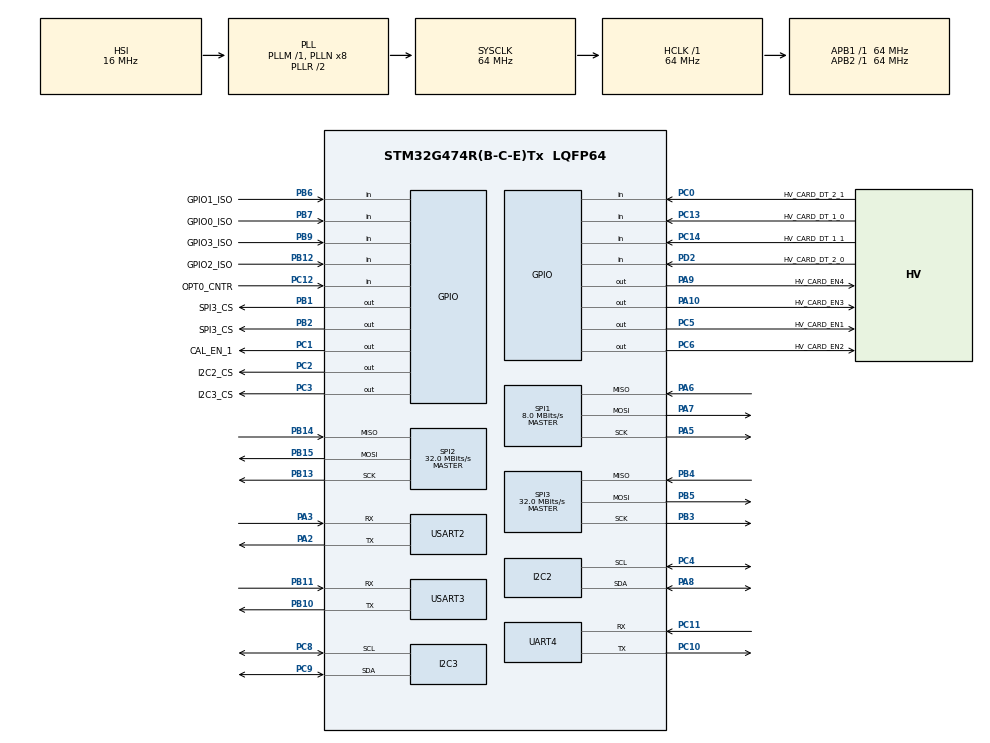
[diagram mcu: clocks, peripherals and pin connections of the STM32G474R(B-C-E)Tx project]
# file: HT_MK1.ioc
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FREERTOS.Tasks01=defaultTask,24,128,StartDefaultTask,Default,NULL,Dynamic,NULL,NULL
FREERTOS.configCHECK_FOR_STACK_OVERFLOW=2
FREERTOS.configTOTAL_HEAP_SIZE=32768
FREERTOS.configUSE_MALLOC_FAILED_HOOK=1
FREERTOS.configUSE_NEWLIB_REENTRANT=1
I2C2.Timing=0x10B17DB5
I2C3.Timing=0x10B17DB5
Mcu.Family=STM32G4
Mcu.Name=STM32G474R(B-C-E)Tx
Mcu.Package=LQFP64
NVIC.PriorityGroup=NVIC_PRIORITYGROUP_4
NVIC.TIM1_UP_TIM16_IRQn=true\:15\:0\:false\:false\:true\:false\:false\:true\:true
NVIC.TimeBase=TIM1_UP_TIM16_IRQn
NVIC.TimeBaseIP=TIM1
PA10.GPIO_Label=HV_CARD_EN3
PA10.PinState=GPIO_PIN_RESET
PA10.Signal=GPIO_Output
PA13.Mode=Serial_Wire
PA13.Signal=SYS_JTMS-SWDIO
PA14.Mode=Serial_Wire
PA14.Signal=SYS_JTCK-SWCLK
PA2.Mode=Asynchronous
PA2.Signal=USART2_TX
PA3.Mode=Asynchronous
PA3.Signal=USART2_RX
PA5.Mode=Full_Duplex_Master
PA5.Signal=SPI1_SCK
PA6.Mode=Full_Duplex_Master
PA6.Signal=SPI1_MISO
PA7.Mode=Full_Duplex_Master
PA7.Signal=SPI1_MOSI
PA8.Mode=I2C
PA8.Signal=I2C2_SDA
PA9.GPIO_Label=HV_CARD_EN4
PA9.PinState=GPIO_PIN_RESET
PA9.Signal=GPIO_Output
PB1.GPIO_Label=SPI3_CS
PB1.Signal=GPIO_Output
PB10.Mode=Asynchronous
PB10.Signal=USART3_TX
PB11.Mode=Asynchronous
PB11.Signal=USART3_RX
PB12.GPIO_Label=GPIO2_ISO
PB12.Signal=GPIO_Input
PB13.Mode=Full_Duplex_Master
PB13.Signal=SPI2_SCK
PB14.Mode=Full_Duplex_Master
PB14.Signal=SPI2_MISO
PB15.Mode=Full_Duplex_Master
PB15.Signal=SPI2_MOSI
PB2.GPIO_Label=SPI3_CS
PB2.Signal=GPIO_Output
PB3.Mode=Full_Duplex_Master
PB3.Signal=SPI3_SCK
PB4.Mode=Full_Duplex_Master
PB4.Signal=SPI3_MISO
PB5.Mode=Full_Duplex_Master
PB5.Signal=SPI3_MOSI
PB6.GPIO_Label=GPIO1_ISO
PB6.Signal=GPIO_Input
PB7.GPIO_Label=GPIO0_ISO
PB7.Signal=GPIO_Input
PB9.GPIO_Label=GPIO3_ISO
PB9.Signal=GPIO_Input
PC0.GPIO_Label=HV_CARD_DT_2_1
PC0.Signal=GPIO_Input
PC1.GPIO_Label=CAL_EN_1
PC1.Signal=GPIO_Output
PC10.Mode=Asynchronous
PC10.Signal=UART4_TX
PC11.Mode=Asynchronous
PC11.Signal=UART4_RX
PC12.GPIO_Label=OPT0_CNTR
PC12.Signal=GPIO_Input
PC13.GPIO_Label=HV_CARD_DT_1_0
PC13.Signal=GPIO_Input
PC14-OSC32_IN.GPIO_Label=HV_CARD_DT_1_1
PC14-OSC32_IN.Signal=GPIO_Input
PC2.GPIO_Label=I2C2_CS
PC2.Signal=GPIO_Output
PC3.GPIO_Label=I2C3_CS
PC3.Signal=GPIO_Output
PC4.Mode=I2C
PC4.Signal=I2C2_SCL
PC5.GPIO_Label=HV_CARD_EN1
PC5.PinState=GPIO_PIN_RESET
PC5.Signal=GPIO_Output
PC6.GPIO_Label=HV_CARD_EN2
PC6.PinState=GPIO_PIN_RESET
PC6.Signal=GPIO_Output
PC8.Mode=I2C
PC8.Signal=I2C3_SCL
PC9.Mode=I2C
PC9.Signal=I2C3_SDA
PD2.GPIO_Label=HV_CARD_DT_2_0
PD2.Signal=GPIO_Input
PF0-OSC_IN.Mode=HSE-External-Oscillator
PF0-OSC_IN.Signal=RCC_OSC_IN
PF1-OSC_OUT.Mode=HSE-External-Oscillator
PF1-OSC_OUT.Signal=RCC_OSC_OUT
ProjectManager.HeapSize=0x200
ProjectManager.StackSize=0x400
ProjectManager.TargetToolchain=STM32CubeIDE
RCC.ADC12Freq_Value=64000000
RCC.ADC345Freq_Value=64000000
RCC.AHBFreq_Value=64000000
RCC.APB1Freq_Value=64000000
RCC.APB1TimFreq_Value=64000000
RCC.APB2Freq_Value=64000000
RCC.APB2TimFreq_Value=64000000
RCC.CortexFreq_Value=64000000
RCC.EXTERNAL_CLOCK_VALUE=12288000
RCC.HCLKFreq_Value=64000000
RCC.HSE_VALUE=16000000
RCC.HSI48_VALUE=48000000
RCC.HSI_VALUE=16000000
RCC.LSE_VALUE=32768
RCC.PLLSourceVirtual=RCC_PLLSOURCE_HSE
RCC.SYSCLKFreq_VALUE=64000000
RCC.SYSCLKSource=RCC_SYSCLKSOURCE_PLLCLK
RCC.USBFreq_Value=64000000
RCC.VCOOutputFreq_Value=128000000
SPI1.BaudRatePrescaler=SPI_BAUDRATEPRESCALER_8
SPI1.CalculateBaudRate=8.0 MBits/s
SPI1.CLKPhase=SPI_PHASE_2EDGE
SPI1.DataSize=SPI_DATASIZE_8BIT
SPI1.Direction=SPI_DIRECTION_2LINES
SPI1.Mode=SPI_MODE_MASTER
SPI1.VirtualType=VM_MASTER
SPI2.CalculateBaudRate=32.0 MBits/s
SPI2.Direction=SPI_DIRECTION_2LINES
SPI2.Mode=SPI_MODE_MASTER
SPI2.VirtualType=VM_MASTER
SPI3.CalculateBaudRate=32.0 MBits/s
SPI3.Direction=SPI_DIRECTION_2LINES
SPI3.Mode=SPI_MODE_MASTER
SPI3.VirtualType=VM_MASTER
USART2.VirtualMode-Asynchronous=VM_ASYNC
USART3.VirtualMode-Asynchronous=VM_ASYNC
VP_FREERTOS_VS_CMSIS_V2.Mode=CMSIS_V2
VP_SYS_VS_DBSignals.Mode=DisableDeadBatterySignals
VP_SYS_VS_tim1.Mode=TIM1
board=custom

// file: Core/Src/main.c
/* USER CODE BEGIN Header */
/**
  ******************************************************************************
  * @file           : main.c
  * @brief          : Main program body
  ******************************************************************************
  * @attention
  *
  * Copyright (c) 2026 STMicroelectronics.
  * All rights reserved.
  *
  * This software is licensed under terms that can be found in the LICENSE file
  * in the root directory of this software component.
  * If no LICENSE file comes with this software, it is provided AS-IS.
  *
  ******************************************************************************
  */
/* USER CODE END Header */
#include "main.h"
#include "cmsis_os.h"
#include "i2c.h"
#include "spi.h"
#include "usart.h"
#include "gpio.h"

/* USER CODE BEGIN Includes */
#include "bsp/board.h"
/* USER CODE END Includes */

void SystemClock_Config(void);
void MX_FREERTOS_Init(void);

int main(void)
{

  /* MCU Configuration--------------------------------------------------------*/

  /* Reset of all peripherals, Initializes the Flash interface and the Systick. */
  HAL_Init();

  /* Configure the system clock */
  SystemClock_Config();

  /* Initialize all configured peripherals */
  MX_GPIO_Init();
  MX_I2C2_Init();
  MX_I2C3_Init();
  MX_SPI1_Init();
  MX_SPI2_Init();
  MX_SPI3_Init();
  MX_UART4_Init();
  MX_USART2_UART_Init();
  MX_USART3_UART_Init();
  /* USER CODE BEGIN 2 */
  /* Bring every card/driver to a safe idle state (HV off, relays/muxes open).
   * Return value intentionally not trapped here so a NAK from the (open-point)
   * matrix I2C isolator does not hang the unit at boot - a card that fails to
   * come up (unseated/missing/faulty) must not stop the rest of the instrument
   * from starting. Board_IsReady() latches the outcome; the sequencer
   * (proto.c) checks it before any hardware command and refuses with a clean
   * ERR EHW instead of running against un-initialised card state. */
  (void)Board_Init();
  /* USER CODE END 2 */

  /* Init scheduler */
  osKernelInitialize();  /* Call init function for freertos objects (in cmsis_os2.c) */
  MX_FREERTOS_Init();

  /* Start scheduler */
  osKernelStart();

  /* We should never get here as control is now taken by the scheduler */

  /* Infinite loop */
  while (1)
  {

  }
}

void SystemClock_Config(void)
{
  RCC_OscInitTypeDef RCC_OscInitStruct = {0};
  RCC_ClkInitTypeDef RCC_ClkInitStruct = {0};

  /** Configure the main internal regulator output voltage
  */
  HAL_PWREx_ControlVoltageScaling(PWR_REGULATOR_VOLTAGE_SCALE1);

  /** Initializes the RCC Oscillators according to the specified parameters
  * in the RCC_OscInitTypeDef structure.
  */
  /* NUCLEO BENCH CLOCK: use the internal 16 MHz HSI instead of the product's
   * external crystal (the Nucleo-G474RE has no 24/16 MHz HSE). 16 MHz x8 /2 =
   * 64 MHz SYSCLK, and HSI_VALUE matches reality so UART baud / delays are
   * correct. Revert to HSE for the product build (also set this in CubeMX). */
  RCC_OscInitStruct.OscillatorType = RCC_OSCILLATORTYPE_HSI;
  RCC_OscInitStruct.HSIState = RCC_HSI_ON;
  RCC_OscInitStruct.HSICalibrationValue = RCC_HSICALIBRATION_DEFAULT;
  RCC_OscInitStruct.PLL.PLLState = RCC_PLL_ON;
  RCC_OscInitStruct.PLL.PLLSource = RCC_PLLSOURCE_HSI;
  RCC_OscInitStruct.PLL.PLLM = RCC_PLLM_DIV1;
  RCC_OscInitStruct.PLL.PLLN = 8;
  RCC_OscInitStruct.PLL.PLLP = RCC_PLLP_DIV2;
  RCC_OscInitStruct.PLL.PLLQ = RCC_PLLQ_DIV2;
  RCC_OscInitStruct.PLL.PLLR = RCC_PLLR_DIV2;
  if (HAL_RCC_OscConfig(&RCC_OscInitStruct) != HAL_OK)
  {
    Error_Handler();
  }

  /** Initializes the CPU, AHB and APB buses clocks
  */
  RCC_ClkInitStruct.ClockType = RCC_CLOCKTYPE_HCLK|RCC_CLOCKTYPE_SYSCLK
                              |RCC_CLOCKTYPE_PCLK1|RCC_CLOCKTYPE_PCLK2;
  RCC_ClkInitStruct.SYSCLKSource = RCC_SYSCLKSOURCE_PLLCLK;
  RCC_ClkInitStruct.AHBCLKDivider = RCC_SYSCLK_DIV1;
  RCC_ClkInitStruct.APB1CLKDivider = RCC_HCLK_DIV1;
  RCC_ClkInitStruct.APB2CLKDivider = RCC_HCLK_DIV1;

  if (HAL_RCC_ClockConfig(&RCC_ClkInitStruct, FLASH_LATENCY_2) != HAL_OK)
  {
    Error_Handler();
  }
}

void HAL_TIM_PeriodElapsedCallback(TIM_HandleTypeDef *htim)
{
  if (htim->Instance == TIM1)
  {
    HAL_IncTick();
  }
}

void Error_Handler(void)
{
  __disable_irq();
  while (1)
  {
  }
}

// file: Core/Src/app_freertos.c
/* USER CODE BEGIN Header */
/**
  ******************************************************************************
  * File Name          : app_freertos.c
  * Description        : Code for freertos applications
  ******************************************************************************
  * @attention
  *
  * Copyright (c) 2026 STMicroelectronics.
  * All rights reserved.
  *
  * This software is licensed under terms that can be found in the LICENSE file
  * in the root directory of this software component.
  * If no LICENSE file comes with this software, it is provided AS-IS.
  *
  ******************************************************************************
  */
/* USER CODE END Header */

#include "FreeRTOS.h"
#include "task.h"
#include "main.h"
#include "cmsis_os.h"

/* USER CODE BEGIN Includes */
#include "app/tasks.h"
/* USER CODE END Includes */

/* Definitions for defaultTask */
osThreadId_t defaultTaskHandle;
const osThreadAttr_t defaultTask_attributes = {
  .name = "defaultTask",
  .priority = (osPriority_t) osPriorityNormal,
  .stack_size = 128 * 4
};

void StartDefaultTask(void *argument);

void MX_FREERTOS_Init(void); /* (MISRA C 2004 rule 8.1) */

void MX_FREERTOS_Init(void) {

  /* Create the thread(s) */
  /* creation of defaultTask */
  defaultTaskHandle = osThreadNew(StartDefaultTask, NULL, &defaultTask_attributes);

  /* USER CODE BEGIN RTOS_THREADS */
  /* Start the harness-tester task architecture (safety / sequencer / comms /
   * logger). The CubeMX defaultTask above stays as a harmless idle thread. */
  Tasks_Init();
  /* USER CODE END RTOS_THREADS */

}

void StartDefaultTask(void *argument)
{
  for(;;)
  {
    osDelay(1);
  }
}

/* USER CODE BEGIN Application */

/* Kernel failure hooks (configCHECK_FOR_STACK_OVERFLOW = 2,
 * configUSE_MALLOC_FAILED_HOOK = 1). A stack overflow or a failed allocation
 * means the RTOS state can no longer be trusted, and the HV DAC may be holding a
 * non-zero code. Do NOT try to talk to the cards from here (the scheduler and the
 * SPI/I2C timeouts depend on interrupts and on state that may be corrupt): stop
 * and let the independent watchdog (tasks.c, ~500 ms) reset the MCU. Board_Init()
 * then runs first and leaves the DAC at 0 V with every relay open. The watchdog
 * is not refreshed here, so this cannot mask itself. */
void vApplicationStackOverflowHook(TaskHandle_t xTask, char *pcTaskName)
{
  (void)xTask;
  (void)pcTaskName;
  __disable_irq();
  for (;;) { }
}

void vApplicationMallocFailedHook(void)
{
  __disable_irq();
  for (;;) { }
}

/* USER CODE END Application */
